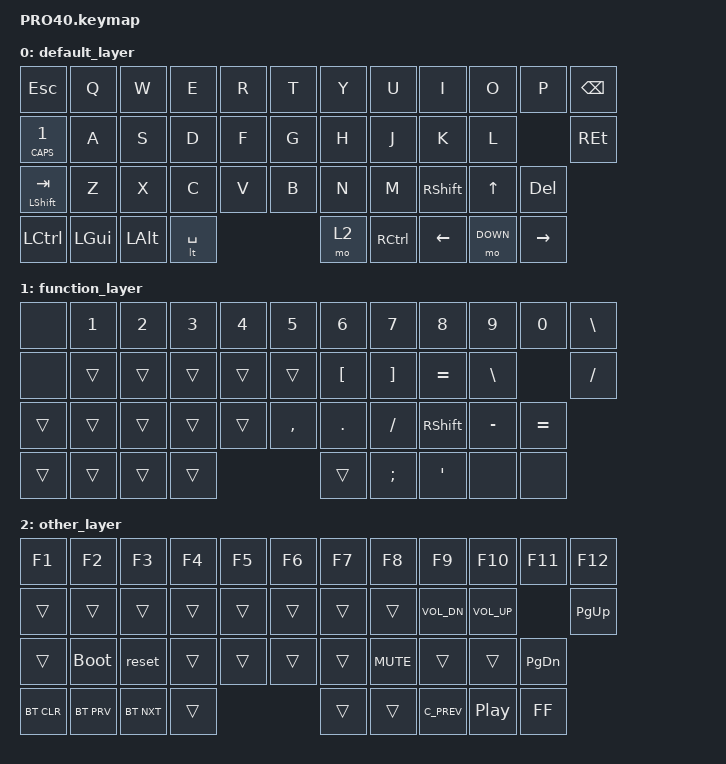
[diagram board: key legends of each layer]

#include <behaviors.dtsi>
#include <dt-bindings/zmk/keys.h>
#include <dt-bindings/zmk/bt.h>

/ {
	behaviors {
		ht: hold_tap {
			compatible = "zmk,behavior-hold-tap";
			label = "Hold Tap";
			#binding-cells = <2>;
			tapping-term-ms = <200>;
			flavor = "tap-preferred";
			bindings = <&kp>, <&kp>;
		};
	};

	keymap {
		compatible = "zmk,keymap";

		default_layer {
			bindings = <
&kp ESC         &kp Q      &kp W      &kp E       &kp R     &kp T    &kp Y    &kp U       &kp I        &kp O      &kp P      &kp BSPC
&lt1 CAPS 1     &kp A      &kp S      &kp D       &kp F     &kp G    &kp H    &kp J       &kp K        &kp L                 &kp REt
&ht LSHFT TAB   &kp Z      &kp X      &kp C       &kp V     &kp B    &kp N    &kp M       &kp RSHFT    &kp UP     &kp DEL
&kp LCTRL       &kp LGUI   &kp LALT   &lt SPACE                      &mo 2    &kp RCTRL   &kp LEFT     &mo DOWN   &kp RIGHT
			>;
		};

		function_layer {
			bindings = <
&none        &kp N1     &kp N2     &kp N3     &kp N4    &kp N5      &kp N6    &kp N7        &kp N8      &kp N9     &kp N0     &kp BSLH 
&none        &trans     &trans     &trans     &trans    &trans      &kp LBKT  &kp RBKT      &kp EQUAL   &kp BSLH   &kp FSLH    
&trans       &trans     &trans     &trans     &trans    &kp COMMA   &kp DOT   &kp SLASH     &kp RSHFT   &kp MINUS  &kp EQUAL          
&trans       &trans     &trans     &trans                           &trans    &kp SEMI      &kp SQT       &none    &none
			>;
		};

		other_layer {
			bindings = <
&kp F1 &kp F2  &kp F3      &kp F4     &kp F5     &kp F6  &kp F7 &kp F8 &kp F9        &kp F10       &kp F11        &kp F12
&trans         &trans      &trans     &trans     &trans  &trans &trans &trans        &kp C_VOL_DN  &kp C_VOL_UP   &kp PAGE_UP
&trans         &bootloader &reset     &trans     &trans  &trans &trans &kp C_MUTE    &trans        &trans         &kp PAGE_DOWN
&bt BT_CLR     &bt BT_PRV  &bt BT_NXT &trans                    &trans &trans C_PREV &kp C_PP                     &kp C_FF
			>;
		};

	};
};
